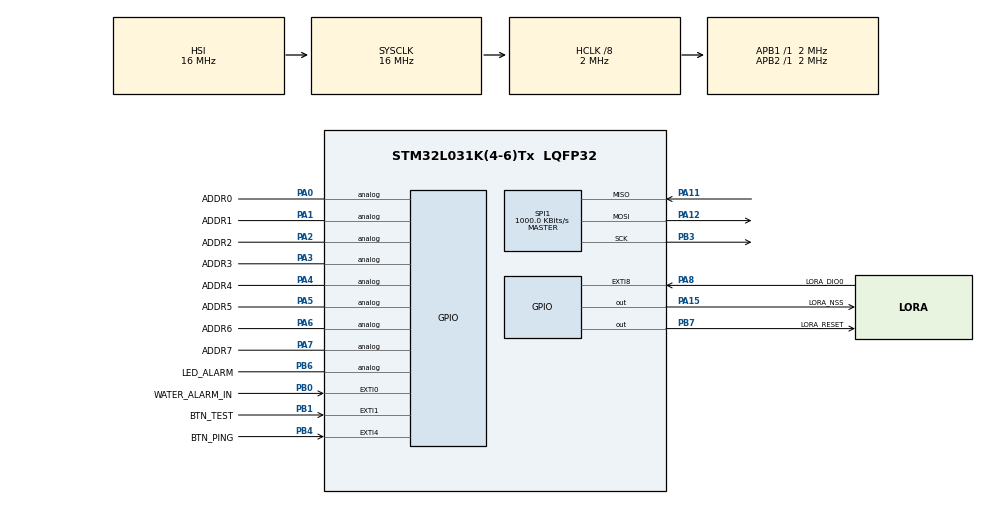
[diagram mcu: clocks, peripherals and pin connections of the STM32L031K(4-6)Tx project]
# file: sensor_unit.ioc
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CRC.InputDataFormat=CRC_INPUTDATA_FORMAT_WORDS
Mcu.Family=STM32L0
Mcu.Name=STM32L031K(4-6)Tx
Mcu.Package=LQFP32
NVIC.EXTI0_1_IRQn=true\:0\:0\:false\:false\:true\:true\:true\:true
NVIC.EXTI4_15_IRQn=true\:0\:0\:false\:false\:true\:true\:true\:true
NVIC.TIM2_IRQn=true\:0\:0\:false\:false\:true\:true\:true\:true
PA0-CK_IN.GPIO_Label=ADDR0
PA0-CK_IN.Signal=GPIO_Analog
PA1.GPIO_Label=ADDR1
PA1.Signal=GPIO_Analog
PA11.GPIO_PuPd=GPIO_PULLUP
PA11.GPIO_Speed=GPIO_SPEED_FREQ_HIGH
PA11.Mode=Full_Duplex_Master
PA11.Signal=SPI1_MISO
PA12.GPIO_PuPd=GPIO_NOPULL
PA12.GPIO_Speed=GPIO_SPEED_FREQ_HIGH
PA12.Mode=Full_Duplex_Master
PA12.Signal=SPI1_MOSI
PA13.Mode=Serial_Wire
PA13.Signal=SYS_SWDIO
PA14.Mode=Serial_Wire
PA14.Signal=SYS_SWCLK
PA15.GPIO_Label=LORA_NSS
PA15.GPIO_PuPd=GPIO_PULLUP
PA15.PinState=GPIO_PIN_SET
PA15.Signal=GPIO_Output
PA2.GPIO_Label=ADDR2
PA2.Signal=GPIO_Analog
PA3.GPIO_Label=ADDR3
PA3.Signal=GPIO_Analog
PA4.GPIO_Label=ADDR4
PA4.Signal=GPIO_Analog
PA5.GPIO_Label=ADDR5
PA5.Signal=GPIO_Analog
PA6.GPIO_Label=ADDR6
PA6.Signal=GPIO_Analog
PA7.GPIO_Label=ADDR7
PA7.Signal=GPIO_Analog
PA8.GPIO_Label=LORA_DIO0
PA8.Signal=GPXTI8
PB0.GPIO_Label=WATER_ALARM_IN
PB0.GPIO_ModeDefaultEXTI=GPIO_MODE_IT_RISING
PB0.GPIO_PuPd=GPIO_NOPULL
PB0.Signal=GPXTI0
PB1.GPIO_Label=BTN_TEST
PB1.GPIO_ModeDefaultEXTI=GPIO_MODE_IT_FALLING
PB1.Signal=GPXTI1
PB3.GPIO_Speed=GPIO_SPEED_FREQ_HIGH
PB3.Mode=Full_Duplex_Master
PB3.Signal=SPI1_SCK
PB4.GPIO_Label=BTN_PING
PB4.GPIO_ModeDefaultEXTI=GPIO_MODE_IT_FALLING
PB4.GPIO_PuPd=GPIO_NOPULL
PB4.Signal=GPXTI4
PB6.GPIO_Label=LED_ALARM
PB6.Signal=GPIO_Analog
PB7.GPIO_Label=LORA_RESET
PB7.PinState=GPIO_PIN_SET
PB7.Signal=GPIO_Output
PC14-OSC32_IN.Mode=LSE-External-Oscillator
PC14-OSC32_IN.Signal=RCC_OSC32_IN
PC15-OSC32_OUT.Mode=LSE-External-Oscillator
PC15-OSC32_OUT.Signal=RCC_OSC32_OUT
ProjectManager.HeapSize=0x200
ProjectManager.StackSize=0x400
ProjectManager.TargetToolchain=CMake
RCC.AHBCLKDivider=RCC_SYSCLK_DIV8
RCC.AHBFreq_Value=2000000
RCC.APB1Freq_Value=2000000
RCC.APB1TimFreq_Value=2000000
RCC.APB2Freq_Value=2000000
RCC.APB2TimFreq_Value=2000000
RCC.HCLKFreq_Value=2000000
RCC.HSE_VALUE=8000000
RCC.HSI16_VALUE=16000000
RCC.HSI_VALUE=16000000
RCC.LptimClockSelection=RCC_LPTIM1CLKSOURCE_LSE
RCC.MSI_VALUE=2097000
RCC.PLLMUL=RCC_PLLMUL_8
RCC.RTCClockSelection=RCC_RTCCLKSOURCE_LSE
RCC.RTCClockSelectionVirtual=RCC_RTCCLKSOURCE_LSE
RCC.SYSCLKFreq_VALUE=16000000
RCC.SYSCLKSource=RCC_SYSCLKSOURCE_HSI
RCC.VCOOutputFreq_Value=128000000
RTC.WakeUpClock-WakeUp=RTC_WAKEUPCLOCK_CK_SPRE_16BITS
RTC.WakeUpCounter-WakeUp=43200
SPI1.CalculateBaudRate=1000.0 KBits/s
SPI1.Direction=SPI_DIRECTION_2LINES
SPI1.Mode=SPI_MODE_MASTER
SPI1.VirtualType=VM_MASTER
TIM2.Period=99
TIM2.Prescaler=1999
VP_ADC_Vref_Input.Mode=IN-Vrefint
VP_CRC_VS_CRC.Mode=CRC_Activate
VP_RTC_VS_RTC_Activate.Mode=RTC_Enabled
VP_RTC_VS_RTC_WakeUp_intern.Mode=WakeUp
VP_TIM2_VS_ClockSourceINT.Mode=Internal
board=custom

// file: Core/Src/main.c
/* USER CODE BEGIN Header */
/**
  ******************************************************************************
  * @file           : main.c
  * @brief          : Main program body
  ******************************************************************************
  * @attention
  *
  * Copyright (c) 2024 STMicroelectronics.
  * All rights reserved.
  *
  * This software is licensed under terms that can be found in the LICENSE file
  * in the root directory of this software component.
  * If no LICENSE file comes with this software, it is provided AS-IS.
  *
  ******************************************************************************
  */
/* USER CODE END Header */
#include "main.h"
#include "adc.h"
#include "crc.h"
#include "rtc.h"
#include "spi.h"
#include "tim.h"
#include "gpio.h"

/* USER CODE BEGIN Includes */
#include "app_main.h"
/* USER CODE END Includes */

void SystemClock_Config(void);

int main(void)
{

  /* MCU Configuration--------------------------------------------------------*/

  /* Reset of all peripherals, Initializes the Flash interface and the Systick. */
  HAL_Init();

  /* Configure the system clock */
  SystemClock_Config();

  /* Initialize all configured peripherals */
  MX_GPIO_Init();
  MX_SPI1_Init();
  MX_ADC_Init();
  MX_CRC_Init();
  MX_RTC_Init();
  MX_TIM2_Init();
  /* USER CODE BEGIN 2 */
  DeviceControl_Init();
  /* USER CODE END 2 */

  /* Infinite loop */
  /* USER CODE BEGIN WHILE */
  while (1)
  {
    DeviceControl_Process();
    /* USER CODE END WHILE */

  }
}

void SystemClock_Config(void)
{
  RCC_OscInitTypeDef RCC_OscInitStruct = {0};
  RCC_ClkInitTypeDef RCC_ClkInitStruct = {0};
  RCC_PeriphCLKInitTypeDef PeriphClkInit = {0};

  /** Configure the main internal regulator output voltage
  */
  __HAL_PWR_VOLTAGESCALING_CONFIG(PWR_REGULATOR_VOLTAGE_SCALE1);

  /** Configure LSE Drive Capability
  */
  HAL_PWR_EnableBkUpAccess();
  __HAL_RCC_LSEDRIVE_CONFIG(RCC_LSEDRIVE_LOW);

  /** Initializes the RCC Oscillators according to the specified parameters
  * in the RCC_OscInitTypeDef structure.
  */
  RCC_OscInitStruct.OscillatorType = RCC_OSCILLATORTYPE_HSI|RCC_OSCILLATORTYPE_LSE;
  RCC_OscInitStruct.LSEState = RCC_LSE_ON;
  RCC_OscInitStruct.HSIState = RCC_HSI_ON;
  RCC_OscInitStruct.HSICalibrationValue = RCC_HSICALIBRATION_DEFAULT;
  RCC_OscInitStruct.PLL.PLLState = RCC_PLL_NONE;
  if (HAL_RCC_OscConfig(&RCC_OscInitStruct) != HAL_OK)
  {
    Error_Handler();
  }

  /** Initializes the CPU, AHB and APB buses clocks
  */
  RCC_ClkInitStruct.ClockType = RCC_CLOCKTYPE_HCLK|RCC_CLOCKTYPE_SYSCLK
                              |RCC_CLOCKTYPE_PCLK1|RCC_CLOCKTYPE_PCLK2;
  RCC_ClkInitStruct.SYSCLKSource = RCC_SYSCLKSOURCE_HSI;
  RCC_ClkInitStruct.AHBCLKDivider = RCC_SYSCLK_DIV8;
  RCC_ClkInitStruct.APB1CLKDivider = RCC_HCLK_DIV1;
  RCC_ClkInitStruct.APB2CLKDivider = RCC_HCLK_DIV1;

  if (HAL_RCC_ClockConfig(&RCC_ClkInitStruct, FLASH_LATENCY_0) != HAL_OK)
  {
    Error_Handler();
  }
  PeriphClkInit.PeriphClockSelection = RCC_PERIPHCLK_RTC;
  PeriphClkInit.RTCClockSelection = RCC_RTCCLKSOURCE_LSE;
  if (HAL_RCCEx_PeriphCLKConfig(&PeriphClkInit) != HAL_OK)
  {
    Error_Handler();
  }
}

void Error_Handler(void)
{
  __disable_irq();
  while (1)
  {
  }
}
